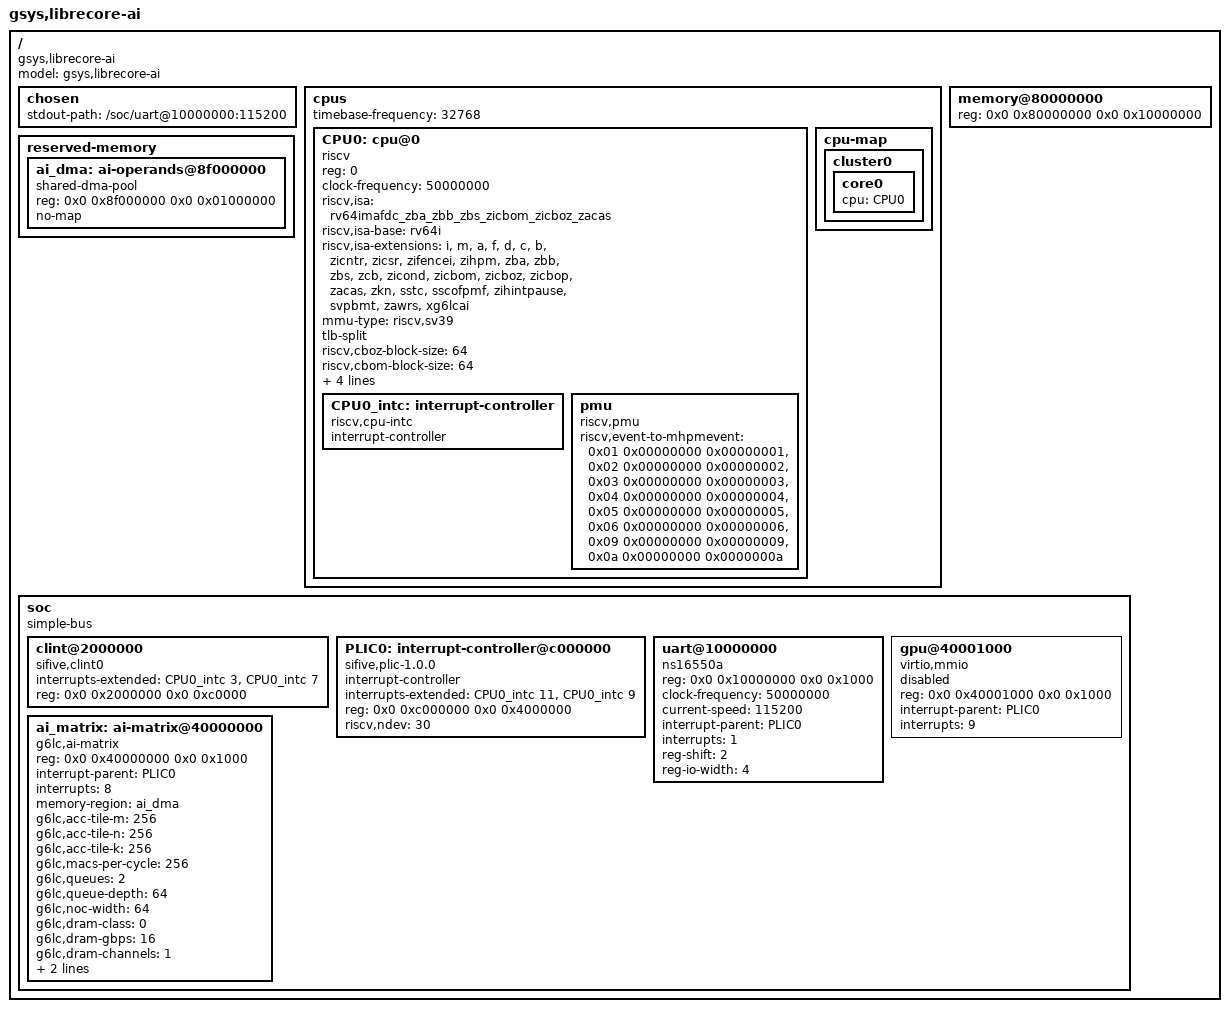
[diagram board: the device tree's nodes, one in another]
// SPDX-License-Identifier: CERN-OHL-S-2.0 OR LicenseRef-GSys-Commercial
// Copyright (c) 2026 Etienne Cimon
//
// AI-enabled single-hart GSys LibreCore DTS for g6lc64_ai + Xg6lcai island.
// Based on ariane-linux.dts topology; adds vendor token xg6lcai and the
// g6lc,ai-matrix MMIO/IRQ node at the GPIO/AI island window.
//
// Hardware map (corev_apu/tb/ariane_soc_pkg.sv + ariane_testharness.sv):
//   MMIO base  = 0x4000_0000 (AiIslandBase / GPIOBase), length 4 KiB
//   PLIC source = 8 (irq_sources[7] = island irq_o)
// Only advertise xg6lcai when AiMatrixEn=1 (g6lc64_ai). Do not use this DTS
// with packages that leave the GPIO window as an error slave.
//
// Board host path: architecture/ai-matrix/board-uio-eventfd.md
// SoftIsland / profile pin: ai-tensor/profiles/island-p3-v1.toml

/dts-v1/;

/ {
  #address-cells = <2>;
  #size-cells = <2>;
  compatible = "gsys,librecore-ai", "eth,ariane-bare-dev";
  model = "gsys,librecore-ai";

  chosen {
    stdout-path = "/soc/uart@10000000:115200";
  };

  cpus {
    #address-cells = <1>;
    #size-cells = <0>;
    timebase-frequency = <32768>;

    CPU0: cpu@0 {
      device_type = "cpu";
      compatible = "riscv";
      reg = <0>;
      status = "okay";
      clock-frequency = <50000000>;
      // Base plane matches ariane-linux; vendor extension token xg6lcai for discovery.
      riscv,isa = "rv64imafdc_zba_zbb_zbs_zicbom_zicboz_zacas";
      riscv,isa-base = "rv64i";
      riscv,isa-extensions = "i", "m", "a", "f", "d", "c", "b",
        "zicntr", "zicsr", "zifencei", "zihpm",
        "zba", "zbb", "zbs",
        "zcb", "zicond",
        "zicbom", "zicboz", "zicbop",
        "zacas",
        "zkn",
        "sstc", "sscofpmf", "zihintpause", "svpbmt", "zawrs",
        "xg6lcai";
      mmu-type = "riscv,sv39";
      tlb-split;
      riscv,cboz-block-size = <64>;
      riscv,cbom-block-size = <64>;
      i-cache-block-size = <16>;
      i-cache-size = <16384>;
      d-cache-block-size = <16>;
      d-cache-size = <32768>;

      CPU0_intc: interrupt-controller {
        #interrupt-cells = <1>;
        interrupt-controller;
        compatible = "riscv,cpu-intc";
      };

      pmu {
        compatible = "riscv,pmu";
        riscv,event-to-mhpmevent =
          <0x01 0x00000000 0x00000001>,
          <0x02 0x00000000 0x00000002>,
          <0x03 0x00000000 0x00000003>,
          <0x04 0x00000000 0x00000004>,
          <0x05 0x00000000 0x00000005>,
          <0x06 0x00000000 0x00000006>,
          <0x09 0x00000000 0x00000009>,
          <0x0a 0x00000000 0x0000000a>;
      };
    };

    cpu-map {
      cluster0 {
        core0 {
          cpu = <&CPU0>;
        };
      };
    };
  };

  memory@80000000 {
    device_type = "memory";
    reg = <0x0 0x80000000 0x0 0x10000000>;
  };

  /* Operand window for in-guest ai-tensor over UIO.
   *
   * The island DMAs A/B/C, so operands must live in a guest-physical range it can
   * reach and the kernel will not hand to something else. `no-map` keeps it out of
   * the linear map so a userspace mmap of the range is the only view of it, which is
   * what makes `/dev/mem` + AI_TENSOR_DMA_BASE safe rather than merely convenient.
   *
   * Still one memory@ node: this is a carve-out of the same DRAM the cores use, not a
   * second address space. Sized for one AccTile=256 job triple (2*256*256 int8 inputs
   * + 256*256 int32 C = 384 KiB) with headroom.
   */
  reserved-memory {
    #address-cells = <2>;
    #size-cells = <2>;
    ranges;

    ai_dma: ai-operands@8f000000 {
      compatible = "shared-dma-pool";
      reg = <0x0 0x8f000000 0x0 0x01000000>;
      no-map;
    };
  };

  soc {
    #address-cells = <2>;
    #size-cells = <2>;
    compatible = "simple-bus";
    ranges;

    clint@2000000 {
      compatible = "sifive,clint0", "riscv,clint0";
      interrupts-extended = <&CPU0_intc 3>, <&CPU0_intc 7>;
      reg = <0x0 0x2000000 0x0 0xc0000>;
    };

    PLIC0: interrupt-controller@c000000 {
      compatible = "sifive,plic-1.0.0", "riscv,plic0";
      #address-cells = <0>;
      #interrupt-cells = <1>;
      interrupt-controller;
      interrupts-extended = <&CPU0_intc 11>, <&CPU0_intc 9>;
      reg = <0x0 0xc000000 0x0 0x4000000>;
      riscv,ndev = <30>;
    };

    uart@10000000 {
      compatible = "ns16550a";
      reg = <0x0 0x10000000 0x0 0x1000>;
      clock-frequency = <50000000>;
      current-speed = <115200>;
      interrupt-parent = <&PLIC0>;
      interrupts = <1>;
      reg-shift = <2>;
      reg-io-width = <4>;
    };

    // LibreCore APU guest window. status=disabled until testharness
    // instantiates g6lc_apu_soc. PLIC source 9 (irq_sources[8]); source 8
    // is the AI island below. Firmware control at 0x40002000 is omitted.
    gpu@40001000 {
      compatible = "virtio,mmio";
      reg = <0x0 0x40001000 0x0 0x1000>;
      interrupt-parent = <&PLIC0>;
      interrupts = <9>;
      status = "disabled";
    };

    // Xg6lcai island — CAP/CTL/doorbell/regions/desc/PMU (4 KiB APB window).
    // Geometry must track CAP words / g6lc_ai_island_cfg (I1 AccTile=256).
    ai_matrix: ai-matrix@40000000 {
      /* "generic-uio" is the fallback compatible `uio_pdrv_genirq` matches, so an
       * in-guest runtime binds the window and the PLIC-8 line with a stock kernel and
       * no out-of-tree driver. The vendor string stays first: a future in-kernel driver
       * must win over the generic bind. The alternative -- a
       * `uio_pdrv_genirq.of_id=g6lc,ai-matrix` command line -- also works and is what
       * a kernel built without this fallback needs.
       * Contract: architecture/ai-matrix/board-uio-eventfd.md
       */
      compatible = "g6lc,ai-matrix", "generic-uio";
      reg = <0x0 0x40000000 0x0 0x1000>;
      interrupt-parent = <&PLIC0>;
      interrupts = <8>;
      /* Operands are DMAed from the reserved carve-out above; ai-tensor reads its
       * base and size from here rather than being told on the command line. */
      memory-region = <&ai_dma>;
      // Discovery helpers for userspace / UIO bind (not Linux ABI yet).
      g6lc,acc-tile-m = <256>;
      g6lc,acc-tile-n = <256>;
      g6lc,acc-tile-k = <256>;
      g6lc,macs-per-cycle = <256>;
      g6lc,queues = <2>;
      g6lc,queue-depth = <64>;
      g6lc,noc-width = <64>;
      g6lc,dram-class = <0>;
      g6lc,dram-gbps = <16>;
      /* Live N=1 class 0. CLASS1 / CHANS_{2,4,8} still one memory@; hardware
       * stripe on the shared DRAM slave (cores + island). CAP 0x38 packs
       * count+shift; 0x34 class; 0x48 init_done. Do not add per-channel memory@. */
      g6lc,dram-channels = <1>;
      g6lc,dram-chan-shift = <6>;
      g6lc,max-ar-out = <2>;
      /* init_done / timing_en are runtime CAP 0x48, not DT. */
      status = "okay";
    };
  };
};
